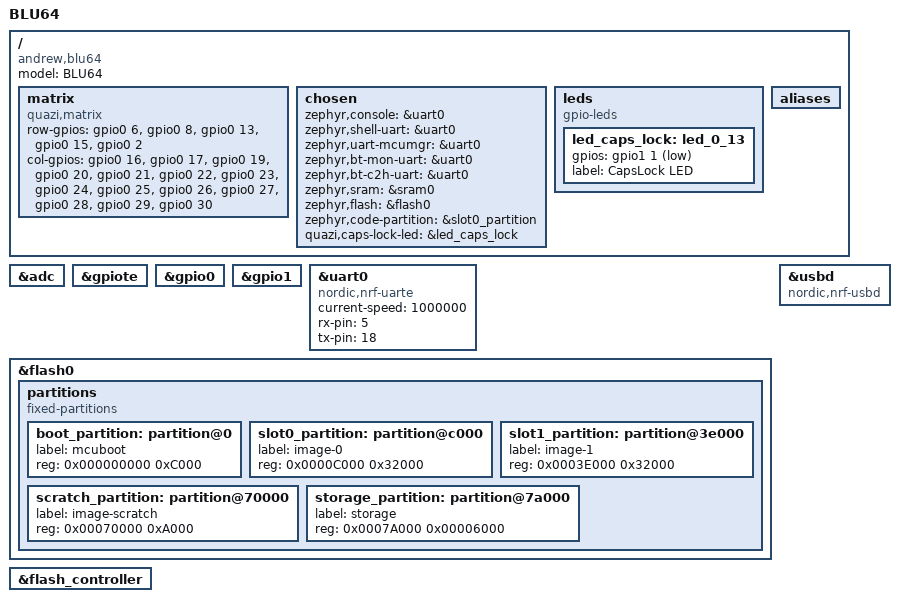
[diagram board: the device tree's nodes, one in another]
/*
 * Copyright (c) 2019 Nordic Semiconductor ASA
 *
 * SPDX-License-Identifier: Apache-2.0
 */

/dts-v1/;
#include <nordic/nrf52833_qiaa.dtsi>

/ {
	model = "BLU64";
	compatible = "andrew,blu64";

	matrix: matrix {
		compatible = "quazi,matrix";
		row-gpios = <&gpio0 6  0>,
		            <&gpio0 8  0>,
		            <&gpio0 13  0>,
		            <&gpio0 15  0>,
		            <&gpio0 2 0>;
		col-gpios = <&gpio0 16 0>,
		            <&gpio0 17 0>,
		            <&gpio0 19 0>,
		            <&gpio0 20 0>,
		            <&gpio0 21 0>,
		            <&gpio0 22 0>,
		            <&gpio0 23 0>,
		            <&gpio0 24 0>,
		            <&gpio0 25 0>,
		            <&gpio0 26 0>,
		            <&gpio0 27 0>,
		            <&gpio0 28 0>,
		            <&gpio0 29 0>,
		            <&gpio0 30 0>;
	};

	chosen {
		zephyr,console = &uart0;
		zephyr,shell-uart = &uart0;
		zephyr,uart-mcumgr = &uart0;
		zephyr,bt-mon-uart = &uart0;
		zephyr,bt-c2h-uart = &uart0;
		zephyr,sram = &sram0;
		zephyr,flash = &flash0;
		zephyr,code-partition = &slot0_partition;

		quazi,caps-lock-led = &led_caps_lock;
	};

	leds {
		compatible = "gpio-leds";
		led_caps_lock: led_0_13 {
			gpios = <&gpio1 1 GPIO_ACTIVE_LOW>;
			label = "CapsLock LED";
		};
	};

	aliases {
	};
};

&adc {
	status = "okay";
};

&gpiote {
	status = "okay";
};

&gpio0 {
	status = "okay";
};

&gpio1 {
	status = "okay";
};

&uart0 {
	status = "okay";
	compatible = "nordic,nrf-uarte";
	current-speed = <1000000>;
	rx-pin = <5>;
	tx-pin = <18>;
};

&flash0 {

	partitions {
		compatible = "fixed-partitions";
		#address-cells = <1>;
		#size-cells = <1>;

		boot_partition: partition@0 {
			label = "mcuboot";
			reg = <0x000000000 0xC000>;
		};
		slot0_partition: partition@c000 {
			label = "image-0";
			reg = <0x0000C000 0x32000>;
		};
		slot1_partition: partition@3e000 {
			label = "image-1";
			reg = <0x0003E000 0x32000>;
		};
		scratch_partition: partition@70000 {
			label = "image-scratch";
			reg = <0x00070000 0xA000>;
		};
		storage_partition: partition@7a000 {
			label = "storage";
			reg = <0x0007A000 0x00006000>;
		};
	};
};

&flash_controller {
	status = "okay";
};

&usbd {
	compatible = "nordic,nrf-usbd";
	status = "okay";
};
